# facedancer register map
Vendor: luna-soc
TODO device.description
Registers are 8-bit, read-write, reset 0x0 unless marked. A register's access mark holds for its fields unless they carry their own. Offsets are from the block's base; lines under a group give offsets from that group; [hi:lo] are bit positions; {n}, {i} and the like mark numbered series; 'fields as' and 'values as' point back to an identical list; <NAME> marks a mode.

## Memory map
0xF0000000 leds size 0x6
0xF0000100 gpio0 size 0x6
0xF0000200 gpio1 size 0x6
0xF0000300 uart0 size 0x14
0xF0000400 uart1 size 0x14
0xF0000500 timer0 size 0x12
0xF0000600 timer1 size 0x12
0xF0000700 spi0 size 0x18
0xF0000800 usb0 size 0xA
0xF0000900 usb0_ep_control size 0x12
0xF0000A00 usb0_ep_in size 0x12
0xF0000B00 usb0_ep_out size 0x22
0xF0000C00 usb1 size 0xA
0xF0000D00 usb1_ep_control size 0x12
0xF0000E00 usb1_ep_in size 0x12
0xF0000F00 usb1_ep_out size 0x22
0xF0001000 usb2 size 0xA
0xF0001100 usb2_ep_control size 0x12
0xF0001200 usb2_ep_in size 0x12
0xF0001300 usb2_ep_out size 0x22
0xF0001400 advertiser size 0x1
0xF0001500 info size 0x2

## Interrupts
0 timer0
1 timer1
2 usb0
3 usb0_ep_control
4 usb0_ep_in
5 usb0_ep_out
6 usb1
7 usb1_ep_control
8 usb1_ep_in
9 usb1_ep_out
10 usb2
11 usb2_ep_control
12 usb2_ep_in
13 usb2_ep_out

## leds
Base 0xF0000000
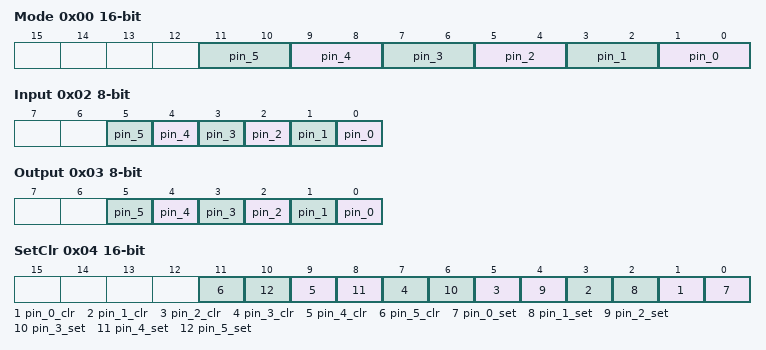
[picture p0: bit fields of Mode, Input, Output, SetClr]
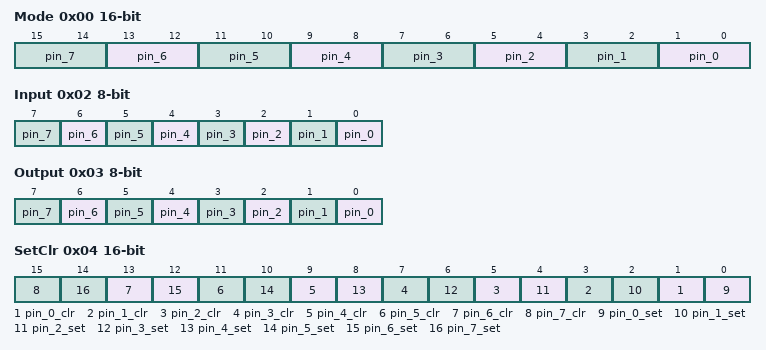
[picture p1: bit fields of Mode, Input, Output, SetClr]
0x00 Mode 16-bit — TODO amaranth_soc/csr/reg.py:471
  [2n+1:2n] pin_{n} (n=0..5) — TODO amaranth_soc/csr/reg.py:471
0x02 Input — TODO amaranth_soc/csr/reg.py:471
  [n] pin_{n} ro (n=0..5) — TODO amaranth_soc/csr/reg.py:471
0x03 Output — TODO amaranth_soc/csr/reg.py:471
  [n] pin_{n} (n=0..5) — TODO amaranth_soc/csr/reg.py:471
0x04 SetClr 16-bit — TODO amaranth_soc/csr/reg.py:471
  [2n+1] pin_{n}_clr wo (n=0..5) — TODO amaranth_soc/csr/reg.py:471
  [2n] pin_{n}_set wo (n=0..5) — TODO amaranth_soc/csr/reg.py:471

## gpio0
Base 0xF0000100
Same registers: gpio1 0xF0000200
0x00 Mode 16-bit — TODO amaranth_soc/csr/reg.py:471
  [2n+1:2n] pin_{n} (n=0..7) — TODO amaranth_soc/csr/reg.py:471
0x02 Input — TODO amaranth_soc/csr/reg.py:471
  [n] pin_{n} ro (n=0..7) — TODO amaranth_soc/csr/reg.py:471
0x03 Output — TODO amaranth_soc/csr/reg.py:471
  [n] pin_{n} (n=0..7) — TODO amaranth_soc/csr/reg.py:471
0x04 SetClr 16-bit — TODO amaranth_soc/csr/reg.py:471
  [2n+1] pin_{n}_clr wo (n=0..7) — TODO amaranth_soc/csr/reg.py:471
  [2n] pin_{n}_set wo (n=0..7) — TODO amaranth_soc/csr/reg.py:471

## uart0
Base 0xF0000300
Same registers: uart1 0xF0000400
0x00 tx_data — TODO amaranth_soc/csr/reg.py:471
  [7:0] data wo
0x04 rx_data — TODO amaranth_soc/csr/reg.py:471
  [7:0] data ro
0x08 tx_ready — TODO amaranth_soc/csr/reg.py:471
  [0] txe ro
0x0C rx_avail — TODO amaranth_soc/csr/reg.py:471
  [0] rxe ro
0x10 divisor 32-bit — TODO amaranth_soc/csr/reg.py:471
  [23:0] div

## timer0
Base 0xF0000500
Same registers: timer1 0xF0000600
0x00 reload 32-bit — TODO amaranth_soc/csr/reg.py:471
  [31:0] value
0x04 enable — TODO amaranth_soc/csr/reg.py:471
  [0] enable
0x08 counter 32-bit — TODO amaranth_soc/csr/reg.py:471
  [31:0] value ro
0x10 ev_enable — TODO amaranth_soc/csr/reg.py:471
  [1:0] mask
0x11 ev_pending — TODO amaranth_soc/csr/reg.py:471
  [1:0] mask

## spi0
Base 0xF0000700
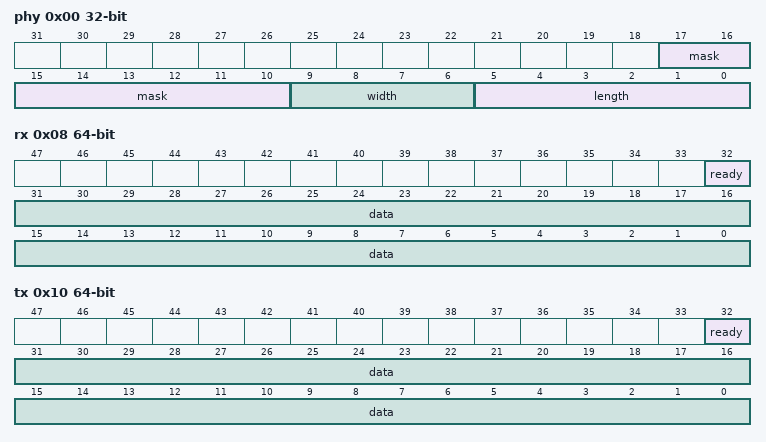
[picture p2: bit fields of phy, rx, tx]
0x00 phy 32-bit — TODO amaranth_soc/csr/reg.py:471
  [17:10] mask — TODO amaranth_soc/csr/reg.py:471
  [9:6] width — TODO amaranth_soc/csr/reg.py:471
  [5:0] length — TODO amaranth_soc/csr/reg.py:471
0x04 cs — TODO amaranth_soc/csr/reg.py:471
  [0] select
0x08 rx 64-bit (reset mask 0xFFFFFFFF) — TODO amaranth_soc/csr/reg.py:471
  [32] ready ro — TODO amaranth_soc/csr/reg.py:471
  [31:0] data ro — TODO amaranth_soc/csr/reg.py:471
0x10 tx 64-bit (reset mask 0xFFFFFFFF) — TODO amaranth_soc/csr/reg.py:471
  [32] ready ro — TODO amaranth_soc/csr/reg.py:471
  [31:0] data wo — TODO amaranth_soc/csr/reg.py:471

## usb0
Base 0xF0000800
Same registers: usb1 0xF0000C00, usb2 0xF0001000
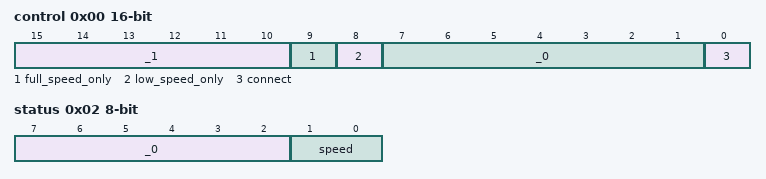
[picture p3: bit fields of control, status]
0x00 control 16-bit — TODO amaranth_soc/csr/reg.py:471
  [15:10] _1 — TODO amaranth_soc/csr/reg.py:471
  [9] full_speed_only — TODO amaranth_soc/csr/reg.py:471
  [8] low_speed_only — TODO amaranth_soc/csr/reg.py:471
  [7:1] _0 — TODO amaranth_soc/csr/reg.py:471
  [0] connect — TODO amaranth_soc/csr/reg.py:471
0x02 status — TODO amaranth_soc/csr/reg.py:471
  [7:2] _0 — TODO amaranth_soc/csr/reg.py:471
  [1:0] speed ro — TODO amaranth_soc/csr/reg.py:471
0x08 ev_enable — TODO amaranth_soc/csr/reg.py:471
  [0] mask
0x09 ev_pending — TODO amaranth_soc/csr/reg.py:471
  [0] mask
